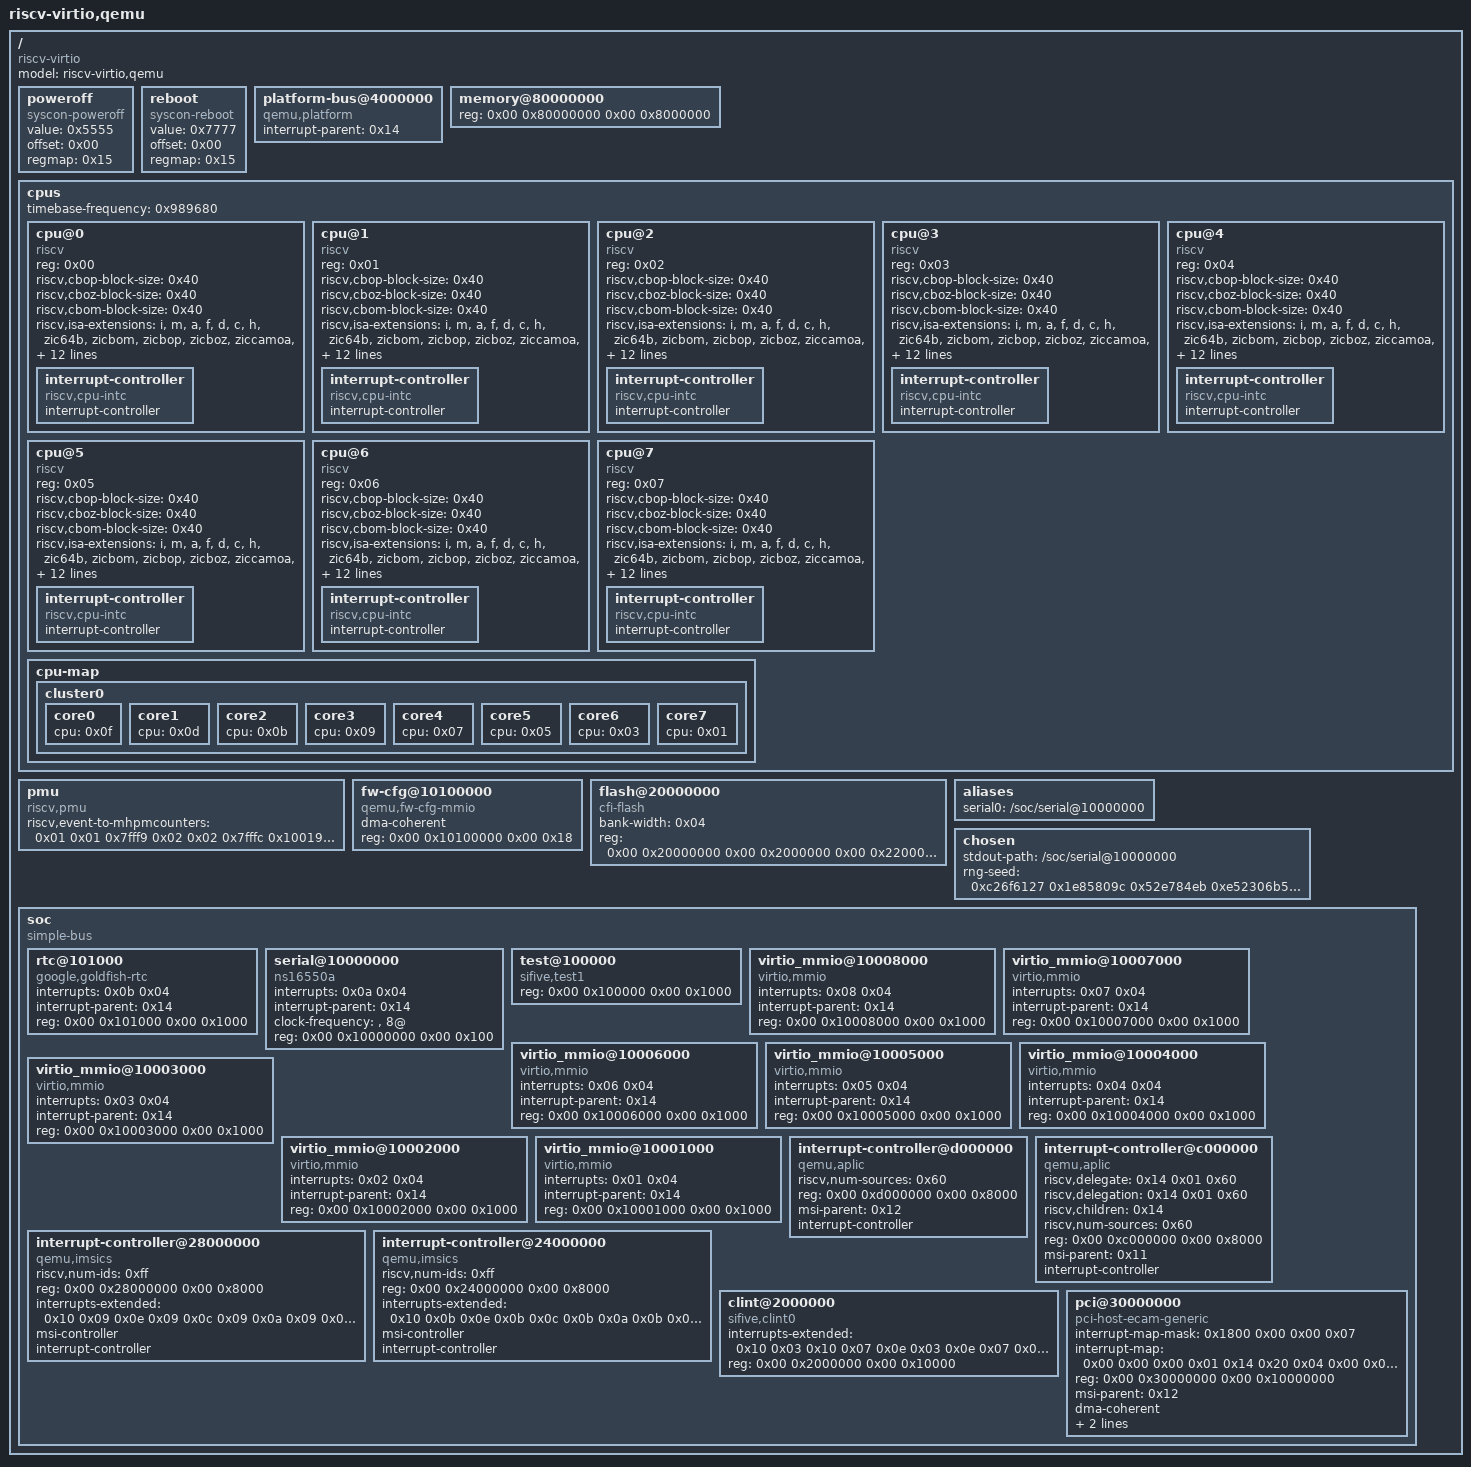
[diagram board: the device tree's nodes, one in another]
/dts-v1/;

/ {
	#address-cells = <0x02>;
	#size-cells = <0x02>;
	compatible = "riscv-virtio";
	model = "riscv-virtio,qemu";

	poweroff {
		value = <0x5555>;
		offset = <0x00>;
		regmap = <0x15>;
		compatible = "syscon-poweroff";
	};

	reboot {
		value = <0x7777>;
		offset = <0x00>;
		regmap = <0x15>;
		compatible = "syscon-reboot";
	};

	platform-bus@4000000 {
		interrupt-parent = <0x14>;
		ranges = <0x00 0x00 0x4000000 0x2000000>;
		#address-cells = <0x01>;
		#size-cells = <0x01>;
		compatible = "qemu,platform", "simple-bus";
	};

	memory@80000000 {
		device_type = "memory";
		reg = <0x00 0x80000000 0x00 0x8000000>;
	};

	cpus {
		#address-cells = <0x01>;
		#size-cells = <0x00>;
		timebase-frequency = <0x989680>;

		cpu@0 {
			phandle = <0x0f>;
			device_type = "cpu";
			reg = <0x00>;
			status = "okay";
			compatible = "riscv";
			riscv,cbop-block-size = <0x40>;
			riscv,cboz-block-size = <0x40>;
			riscv,cbom-block-size = <0x40>;
			riscv,isa-extensions = "i", "m", "a", "f", "d", "c", "h", "zic64b", "zicbom", "zicbop", "zicboz", "ziccamoa", "ziccif", "zicclsm", "ziccrse", "zicntr", "zicsr", "zifencei", "zihintntl", "zihintpause", "zihpm", "zmmul", "za64rs", "zaamo", "zalrsc", "zawrs", "zfa", "zca", "zcd", "zba", "zbb", "zbc", "zbs", "shcounterenw", "shgatpa", "shtvala", "shvsatpa", "shvstvala", "shvstvecd", "smaia", "ssaia", "ssccptr", "sscounterenw", "sstc", "sstvala", "sstvecd", "ssu64xl", "svadu", "svvptc";
			riscv,isa-base = "rv64i";
			riscv,isa = "rv64imafdch_zic64b_zicbom_zicbop_zicboz_ziccamoa_ziccif_zicclsm_ziccrse_zicntr_zicsr_zifencei_zihintntl_zihintpause_zihpm_zmmul_za64rs_zaamo_zalrsc_zawrs_zfa_zca_zcd_zba_zbb_zbc_zbs_shcounterenw_shgatpa_shtvala_shvsatpa_shvstvala_shvstvecd_smaia_ssaia_ssccptr_sscounterenw_sstc_sstvala_sstvecd_ssu64xl_svadu_svvptc";
			mmu-type = "riscv,sv57";

			interrupt-controller {
				#interrupt-cells = <0x01>;
				interrupt-controller;
				compatible = "riscv,cpu-intc";
				phandle = <0x10>;
			};
		};

		cpu@1 {
			phandle = <0x0d>;
			device_type = "cpu";
			reg = <0x01>;
			status = "okay";
			compatible = "riscv";
			riscv,cbop-block-size = <0x40>;
			riscv,cboz-block-size = <0x40>;
			riscv,cbom-block-size = <0x40>;
			riscv,isa-extensions = "i", "m", "a", "f", "d", "c", "h", "zic64b", "zicbom", "zicbop", "zicboz", "ziccamoa", "ziccif", "zicclsm", "ziccrse", "zicntr", "zicsr", "zifencei", "zihintntl", "zihintpause", "zihpm", "zmmul", "za64rs", "zaamo", "zalrsc", "zawrs", "zfa", "zca", "zcd", "zba", "zbb", "zbc", "zbs", "shcounterenw", "shgatpa", "shtvala", "shvsatpa", "shvstvala", "shvstvecd", "smaia", "ssaia", "ssccptr", "sscounterenw", "sstc", "sstvala", "sstvecd", "ssu64xl", "svadu", "svvptc";
			riscv,isa-base = "rv64i";
			riscv,isa = "rv64imafdch_zic64b_zicbom_zicbop_zicboz_ziccamoa_ziccif_zicclsm_ziccrse_zicntr_zicsr_zifencei_zihintntl_zihintpause_zihpm_zmmul_za64rs_zaamo_zalrsc_zawrs_zfa_zca_zcd_zba_zbb_zbc_zbs_shcounterenw_shgatpa_shtvala_shvsatpa_shvstvala_shvstvecd_smaia_ssaia_ssccptr_sscounterenw_sstc_sstvala_sstvecd_ssu64xl_svadu_svvptc";
			mmu-type = "riscv,sv57";

			interrupt-controller {
				#interrupt-cells = <0x01>;
				interrupt-controller;
				compatible = "riscv,cpu-intc";
				phandle = <0x0e>;
			};
		};

		cpu@2 {
			phandle = <0x0b>;
			device_type = "cpu";
			reg = <0x02>;
			status = "okay";
			compatible = "riscv";
			riscv,cbop-block-size = <0x40>;
			riscv,cboz-block-size = <0x40>;
			riscv,cbom-block-size = <0x40>;
			riscv,isa-extensions = "i", "m", "a", "f", "d", "c", "h", "zic64b", "zicbom", "zicbop", "zicboz", "ziccamoa", "ziccif", "zicclsm", "ziccrse", "zicntr", "zicsr", "zifencei", "zihintntl", "zihintpause", "zihpm", "zmmul", "za64rs", "zaamo", "zalrsc", "zawrs", "zfa", "zca", "zcd", "zba", "zbb", "zbc", "zbs", "shcounterenw", "shgatpa", "shtvala", "shvsatpa", "shvstvala", "shvstvecd", "smaia", "ssaia", "ssccptr", "sscounterenw", "sstc", "sstvala", "sstvecd", "ssu64xl", "svadu", "svvptc";
			riscv,isa-base = "rv64i";
			riscv,isa = "rv64imafdch_zic64b_zicbom_zicbop_zicboz_ziccamoa_ziccif_zicclsm_ziccrse_zicntr_zicsr_zifencei_zihintntl_zihintpause_zihpm_zmmul_za64rs_zaamo_zalrsc_zawrs_zfa_zca_zcd_zba_zbb_zbc_zbs_shcounterenw_shgatpa_shtvala_shvsatpa_shvstvala_shvstvecd_smaia_ssaia_ssccptr_sscounterenw_sstc_sstvala_sstvecd_ssu64xl_svadu_svvptc";
			mmu-type = "riscv,sv57";

			interrupt-controller {
				#interrupt-cells = <0x01>;
				interrupt-controller;
				compatible = "riscv,cpu-intc";
				phandle = <0x0c>;
			};
		};

		cpu@3 {
			phandle = <0x09>;
			device_type = "cpu";
			reg = <0x03>;
			status = "okay";
			compatible = "riscv";
			riscv,cbop-block-size = <0x40>;
			riscv,cboz-block-size = <0x40>;
			riscv,cbom-block-size = <0x40>;
			riscv,isa-extensions = "i", "m", "a", "f", "d", "c", "h", "zic64b", "zicbom", "zicbop", "zicboz", "ziccamoa", "ziccif", "zicclsm", "ziccrse", "zicntr", "zicsr", "zifencei", "zihintntl", "zihintpause", "zihpm", "zmmul", "za64rs", "zaamo", "zalrsc", "zawrs", "zfa", "zca", "zcd", "zba", "zbb", "zbc", "zbs", "shcounterenw", "shgatpa", "shtvala", "shvsatpa", "shvstvala", "shvstvecd", "smaia", "ssaia", "ssccptr", "sscounterenw", "sstc", "sstvala", "sstvecd", "ssu64xl", "svadu", "svvptc";
			riscv,isa-base = "rv64i";
			riscv,isa = "rv64imafdch_zic64b_zicbom_zicbop_zicboz_ziccamoa_ziccif_zicclsm_ziccrse_zicntr_zicsr_zifencei_zihintntl_zihintpause_zihpm_zmmul_za64rs_zaamo_zalrsc_zawrs_zfa_zca_zcd_zba_zbb_zbc_zbs_shcounterenw_shgatpa_shtvala_shvsatpa_shvstvala_shvstvecd_smaia_ssaia_ssccptr_sscounterenw_sstc_sstvala_sstvecd_ssu64xl_svadu_svvptc";
			mmu-type = "riscv,sv57";

			interrupt-controller {
				#interrupt-cells = <0x01>;
				interrupt-controller;
				compatible = "riscv,cpu-intc";
				phandle = <0x0a>;
			};
		};

		cpu@4 {
			phandle = <0x07>;
			device_type = "cpu";
			reg = <0x04>;
			status = "okay";
			compatible = "riscv";
			riscv,cbop-block-size = <0x40>;
			riscv,cboz-block-size = <0x40>;
			riscv,cbom-block-size = <0x40>;
			riscv,isa-extensions = "i", "m", "a", "f", "d", "c", "h", "zic64b", "zicbom", "zicbop", "zicboz", "ziccamoa", "ziccif", "zicclsm", "ziccrse", "zicntr", "zicsr", "zifencei", "zihintntl", "zihintpause", "zihpm", "zmmul", "za64rs", "zaamo", "zalrsc", "zawrs", "zfa", "zca", "zcd", "zba", "zbb", "zbc", "zbs", "shcounterenw", "shgatpa", "shtvala", "shvsatpa", "shvstvala", "shvstvecd", "smaia", "ssaia", "ssccptr", "sscounterenw", "sstc", "sstvala", "sstvecd", "ssu64xl", "svadu", "svvptc";
			riscv,isa-base = "rv64i";
			riscv,isa = "rv64imafdch_zic64b_zicbom_zicbop_zicboz_ziccamoa_ziccif_zicclsm_ziccrse_zicntr_zicsr_zifencei_zihintntl_zihintpause_zihpm_zmmul_za64rs_zaamo_zalrsc_zawrs_zfa_zca_zcd_zba_zbb_zbc_zbs_shcounterenw_shgatpa_shtvala_shvsatpa_shvstvala_shvstvecd_smaia_ssaia_ssccptr_sscounterenw_sstc_sstvala_sstvecd_ssu64xl_svadu_svvptc";
			mmu-type = "riscv,sv57";

			interrupt-controller {
				#interrupt-cells = <0x01>;
				interrupt-controller;
				compatible = "riscv,cpu-intc";
				phandle = <0x08>;
			};
		};

		cpu@5 {
			phandle = <0x05>;
			device_type = "cpu";
			reg = <0x05>;
			status = "okay";
			compatible = "riscv";
			riscv,cbop-block-size = <0x40>;
			riscv,cboz-block-size = <0x40>;
			riscv,cbom-block-size = <0x40>;
			riscv,isa-extensions = "i", "m", "a", "f", "d", "c", "h", "zic64b", "zicbom", "zicbop", "zicboz", "ziccamoa", "ziccif", "zicclsm", "ziccrse", "zicntr", "zicsr", "zifencei", "zihintntl", "zihintpause", "zihpm", "zmmul", "za64rs", "zaamo", "zalrsc", "zawrs", "zfa", "zca", "zcd", "zba", "zbb", "zbc", "zbs", "shcounterenw", "shgatpa", "shtvala", "shvsatpa", "shvstvala", "shvstvecd", "smaia", "ssaia", "ssccptr", "sscounterenw", "sstc", "sstvala", "sstvecd", "ssu64xl", "svadu", "svvptc";
			riscv,isa-base = "rv64i";
			riscv,isa = "rv64imafdch_zic64b_zicbom_zicbop_zicboz_ziccamoa_ziccif_zicclsm_ziccrse_zicntr_zicsr_zifencei_zihintntl_zihintpause_zihpm_zmmul_za64rs_zaamo_zalrsc_zawrs_zfa_zca_zcd_zba_zbb_zbc_zbs_shcounterenw_shgatpa_shtvala_shvsatpa_shvstvala_shvstvecd_smaia_ssaia_ssccptr_sscounterenw_sstc_sstvala_sstvecd_ssu64xl_svadu_svvptc";
			mmu-type = "riscv,sv57";

			interrupt-controller {
				#interrupt-cells = <0x01>;
				interrupt-controller;
				compatible = "riscv,cpu-intc";
				phandle = <0x06>;
			};
		};

		cpu@6 {
			phandle = <0x03>;
			device_type = "cpu";
			reg = <0x06>;
			status = "okay";
			compatible = "riscv";
			riscv,cbop-block-size = <0x40>;
			riscv,cboz-block-size = <0x40>;
			riscv,cbom-block-size = <0x40>;
			riscv,isa-extensions = "i", "m", "a", "f", "d", "c", "h", "zic64b", "zicbom", "zicbop", "zicboz", "ziccamoa", "ziccif", "zicclsm", "ziccrse", "zicntr", "zicsr", "zifencei", "zihintntl", "zihintpause", "zihpm", "zmmul", "za64rs", "zaamo", "zalrsc", "zawrs", "zfa", "zca", "zcd", "zba", "zbb", "zbc", "zbs", "shcounterenw", "shgatpa", "shtvala", "shvsatpa", "shvstvala", "shvstvecd", "smaia", "ssaia", "ssccptr", "sscounterenw", "sstc", "sstvala", "sstvecd", "ssu64xl", "svadu", "svvptc";
			riscv,isa-base = "rv64i";
			riscv,isa = "rv64imafdch_zic64b_zicbom_zicbop_zicboz_ziccamoa_ziccif_zicclsm_ziccrse_zicntr_zicsr_zifencei_zihintntl_zihintpause_zihpm_zmmul_za64rs_zaamo_zalrsc_zawrs_zfa_zca_zcd_zba_zbb_zbc_zbs_shcounterenw_shgatpa_shtvala_shvsatpa_shvstvala_shvstvecd_smaia_ssaia_ssccptr_sscounterenw_sstc_sstvala_sstvecd_ssu64xl_svadu_svvptc";
			mmu-type = "riscv,sv57";

			interrupt-controller {
				#interrupt-cells = <0x01>;
				interrupt-controller;
				compatible = "riscv,cpu-intc";
				phandle = <0x04>;
			};
		};

		cpu@7 {
			phandle = <0x01>;
			device_type = "cpu";
			reg = <0x07>;
			status = "okay";
			compatible = "riscv";
			riscv,cbop-block-size = <0x40>;
			riscv,cboz-block-size = <0x40>;
			riscv,cbom-block-size = <0x40>;
			riscv,isa-extensions = "i", "m", "a", "f", "d", "c", "h", "zic64b", "zicbom", "zicbop", "zicboz", "ziccamoa", "ziccif", "zicclsm", "ziccrse", "zicntr", "zicsr", "zifencei", "zihintntl", "zihintpause", "zihpm", "zmmul", "za64rs", "zaamo", "zalrsc", "zawrs", "zfa", "zca", "zcd", "zba", "zbb", "zbc", "zbs", "shcounterenw", "shgatpa", "shtvala", "shvsatpa", "shvstvala", "shvstvecd", "smaia", "ssaia", "ssccptr", "sscounterenw", "sstc", "sstvala", "sstvecd", "ssu64xl", "svadu", "svvptc";
			riscv,isa-base = "rv64i";
			riscv,isa = "rv64imafdch_zic64b_zicbom_zicbop_zicboz_ziccamoa_ziccif_zicclsm_ziccrse_zicntr_zicsr_zifencei_zihintntl_zihintpause_zihpm_zmmul_za64rs_zaamo_zalrsc_zawrs_zfa_zca_zcd_zba_zbb_zbc_zbs_shcounterenw_shgatpa_shtvala_shvsatpa_shvstvala_shvstvecd_smaia_ssaia_ssccptr_sscounterenw_sstc_sstvala_sstvecd_ssu64xl_svadu_svvptc";
			mmu-type = "riscv,sv57";

			interrupt-controller {
				#interrupt-cells = <0x01>;
				interrupt-controller;
				compatible = "riscv,cpu-intc";
				phandle = <0x02>;
			};
		};

		cpu-map {

			cluster0 {

				core0 {
					cpu = <0x0f>;
				};

				core1 {
					cpu = <0x0d>;
				};

				core2 {
					cpu = <0x0b>;
				};

				core3 {
					cpu = <0x09>;
				};

				core4 {
					cpu = <0x07>;
				};

				core5 {
					cpu = <0x05>;
				};

				core6 {
					cpu = <0x03>;
				};

				core7 {
					cpu = <0x01>;
				};
			};
		};
	};

	pmu {
		riscv,event-to-mhpmcounters = <0x01 0x01 0x7fff9 0x02 0x02 0x7fffc 0x10019 0x10019 0x7fff8 0x1001b 0x1001b 0x7fff8 0x10021 0x10021 0x7fff8>;
		compatible = "riscv,pmu";
	};

	fw-cfg@10100000 {
		dma-coherent;
		reg = <0x00 0x10100000 0x00 0x18>;
		compatible = "qemu,fw-cfg-mmio";
	};

	flash@20000000 {
		bank-width = <0x04>;
		reg = <0x00 0x20000000 0x00 0x2000000 0x00 0x22000000 0x00 0x2000000>;
		compatible = "cfi-flash";
	};

	aliases {
		serial0 = "/soc/serial@10000000";
	};

	chosen {
		stdout-path = "/soc/serial@10000000";
		rng-seed = <0xc26f6127 0x1e85809c 0x52e784eb 0xe52306b5 0xf9ac61d 0x385d4b02 0xc467f368 0x7483faac>;
	};

	soc {
		#address-cells = <0x02>;
		#size-cells = <0x02>;
		compatible = "simple-bus";
		ranges;

		rtc@101000 {
			interrupts = <0x0b 0x04>;
			interrupt-parent = <0x14>;
			reg = <0x00 0x101000 0x00 0x1000>;
			compatible = "google,goldfish-rtc";
		};

		serial@10000000 {
			interrupts = <0x0a 0x04>;
			interrupt-parent = <0x14>;
			clock-frequency = "", "8@";
			reg = <0x00 0x10000000 0x00 0x100>;
			compatible = "ns16550a";
		};

		test@100000 {
			phandle = <0x15>;
			reg = <0x00 0x100000 0x00 0x1000>;
			compatible = "sifive,test1", "sifive,test0", "syscon";
		};

		virtio_mmio@10008000 {
			interrupts = <0x08 0x04>;
			interrupt-parent = <0x14>;
			reg = <0x00 0x10008000 0x00 0x1000>;
			compatible = "virtio,mmio";
		};

		virtio_mmio@10007000 {
			interrupts = <0x07 0x04>;
			interrupt-parent = <0x14>;
			reg = <0x00 0x10007000 0x00 0x1000>;
			compatible = "virtio,mmio";
		};

		virtio_mmio@10006000 {
			interrupts = <0x06 0x04>;
			interrupt-parent = <0x14>;
			reg = <0x00 0x10006000 0x00 0x1000>;
			compatible = "virtio,mmio";
		};

		virtio_mmio@10005000 {
			interrupts = <0x05 0x04>;
			interrupt-parent = <0x14>;
			reg = <0x00 0x10005000 0x00 0x1000>;
			compatible = "virtio,mmio";
		};

		virtio_mmio@10004000 {
			interrupts = <0x04 0x04>;
			interrupt-parent = <0x14>;
			reg = <0x00 0x10004000 0x00 0x1000>;
			compatible = "virtio,mmio";
		};

		virtio_mmio@10003000 {
			interrupts = <0x03 0x04>;
			interrupt-parent = <0x14>;
			reg = <0x00 0x10003000 0x00 0x1000>;
			compatible = "virtio,mmio";
		};

		virtio_mmio@10002000 {
			interrupts = <0x02 0x04>;
			interrupt-parent = <0x14>;
			reg = <0x00 0x10002000 0x00 0x1000>;
			compatible = "virtio,mmio";
		};

		virtio_mmio@10001000 {
			interrupts = <0x01 0x04>;
			interrupt-parent = <0x14>;
			reg = <0x00 0x10001000 0x00 0x1000>;
			compatible = "virtio,mmio";
		};

		interrupt-controller@d000000 {
			phandle = <0x14>;
			riscv,num-sources = <0x60>;
			reg = <0x00 0xd000000 0x00 0x8000>;
			msi-parent = <0x12>;
			interrupt-controller;
			#interrupt-cells = <0x02>;
			#address-cells = <0x00>;
			compatible = "qemu,aplic", "riscv,aplic";
		};

		interrupt-controller@c000000 {
			phandle = <0x13>;
			riscv,delegate = <0x14 0x01 0x60>;
			riscv,delegation = <0x14 0x01 0x60>;
			riscv,children = <0x14>;
			riscv,num-sources = <0x60>;
			reg = <0x00 0xc000000 0x00 0x8000>;
			msi-parent = <0x11>;
			interrupt-controller;
			#interrupt-cells = <0x02>;
			#address-cells = <0x00>;
			compatible = "qemu,aplic", "riscv,aplic";
		};

		interrupt-controller@28000000 {
			phandle = <0x12>;
			riscv,num-ids = <0xff>;
			reg = <0x00 0x28000000 0x00 0x8000>;
			interrupts-extended = <0x10 0x09 0x0e 0x09 0x0c 0x09 0x0a 0x09 0x08 0x09 0x06 0x09 0x04 0x09 0x02 0x09>;
			msi-controller;
			interrupt-controller;
			#interrupt-cells = <0x00>;
			compatible = "qemu,imsics", "riscv,imsics";
		};

		interrupt-controller@24000000 {
			phandle = <0x11>;
			riscv,num-ids = <0xff>;
			reg = <0x00 0x24000000 0x00 0x8000>;
			interrupts-extended = <0x10 0x0b 0x0e 0x0b 0x0c 0x0b 0x0a 0x0b 0x08 0x0b 0x06 0x0b 0x04 0x0b 0x02 0x0b>;
			msi-controller;
			interrupt-controller;
			#interrupt-cells = <0x00>;
			compatible = "qemu,imsics", "riscv,imsics";
		};

		clint@2000000 {
			interrupts-extended = <0x10 0x03 0x10 0x07 0x0e 0x03 0x0e 0x07 0x0c 0x03 0x0c 0x07 0x0a 0x03 0x0a 0x07 0x08 0x03 0x08 0x07 0x06 0x03 0x06 0x07 0x04 0x03 0x04 0x07 0x02 0x03 0x02 0x07>;
			reg = <0x00 0x2000000 0x00 0x10000>;
			compatible = "sifive,clint0", "riscv,clint0";
		};

		pci@30000000 {
			interrupt-map-mask = <0x1800 0x00 0x00 0x07>;
			interrupt-map = <0x00 0x00 0x00 0x01 0x14 0x20 0x04 0x00 0x00 0x00 0x02 0x14 0x21 0x04 0x00 0x00 0x00 0x03 0x14 0x22 0x04 0x00 0x00 0x00 0x04 0x14 0x23 0x04 0x800 0x00 0x00 0x01 0x14 0x21 0x04 0x800 0x00 0x00 0x02 0x14 0x22 0x04 0x800 0x00 0x00 0x03 0x14 0x23 0x04 0x800 0x00 0x00 0x04 0x14 0x20 0x04 0x1000 0x00 0x00 0x01 0x14 0x22 0x04 0x1000 0x00 0x00 0x02 0x14 0x23 0x04 0x1000 0x00 0x00 0x03 0x14 0x20 0x04 0x1000 0x00 0x00 0x04 0x14 0x21 0x04 0x1800 0x00 0x00 0x01 0x14 0x23 0x04 0x1800 0x00 0x00 0x02 0x14 0x20 0x04 0x1800 0x00 0x00 0x03 0x14 0x21 0x04 0x1800 0x00 0x00 0x04 0x14 0x22 0x04>;
			ranges = <0x1000000 0x00 0x00 0x00 0x3000000 0x00 0x10000 0x2000000 0x00 0x40000000 0x00 0x40000000 0x00 0x40000000 0x3000000 0x04 0x00 0x04 0x00 0x04 0x00>;
			reg = <0x00 0x30000000 0x00 0x10000000>;
			msi-parent = <0x12>;
			dma-coherent;
			bus-range = <0x00 0xff>;
			linux,pci-domain = <0x00>;
			device_type = "pci";
			compatible = "pci-host-ecam-generic";
			#size-cells = <0x02>;
			#interrupt-cells = <0x01>;
			#address-cells = <0x03>;
		};
	};
};
